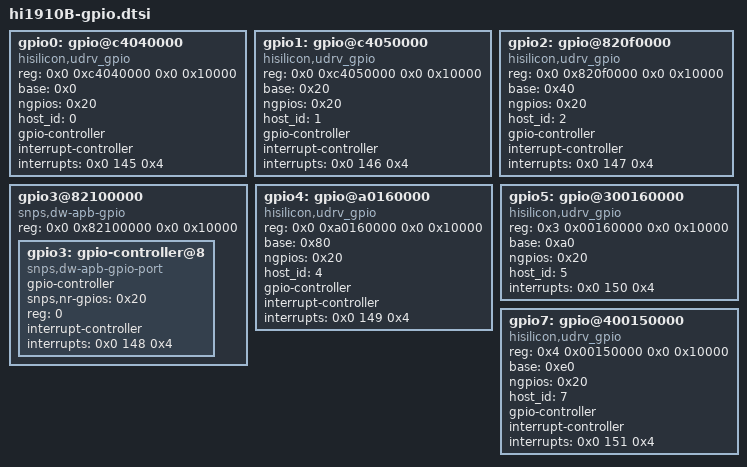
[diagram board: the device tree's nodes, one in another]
	gpio0:gpio@c4040000 {
		compatible = "hisilicon,udrv_gpio";
		reg = <0x0 0xc4040000 0x0 0x10000>;
		base = <0x0>;
		ngpios = <0x20>;
		host_id = <0>;
		gpio-controller;
		#gpio-cells = <2>;
		interrupt-controller;
		#interrupt-cells = <2>;
		interrupts = <0x0 145 0x4>;
	};

	gpio1:gpio@c4050000 {
		compatible = "hisilicon,udrv_gpio";
		reg = <0x0 0xc4050000 0x0 0x10000>;
		base = <0x20>;
		ngpios = <0x20>;
		host_id = <1>;
		gpio-controller;
		#gpio-cells = <2>;
		interrupt-controller;
		#interrupt-cells = <2>;
		interrupts = <0x0 146 0x4>;
	};

	gpio2:gpio@820f0000 {
		compatible = "hisilicon,udrv_gpio";
		reg = <0x0 0x820f0000 0x0 0x10000>;
		base = <0x40>;
		ngpios = <0x20>;
		host_id = <2>;
		gpio-controller;
		#gpio-cells = <2>;
		interrupt-controller;
		#interrupt-cells = <2>;
		interrupts = <0x0 147 0x4>;
	};

	gpio3@82100000 {
		compatible = "snps,dw-apb-gpio";
		reg = <0x0 0x82100000 0x0 0x10000>;
		#address-cells = <1>;
		#size-cells = <0>;

		gpio3:gpio-controller@8 {
			compatible = "snps,dw-apb-gpio-port";
			gpio-controller;
			#gpio-cells = <2>;
			snps,nr-gpios = <0x20>;
			reg = <0>;
			interrupt-controller;
			#interrupt-cells = <2>;
			interrupts = <0x0 148 0x4>;
		};
	};

	gpio4:gpio@a0160000 {
		compatible = "hisilicon,udrv_gpio";
		reg = <0x0 0xa0160000 0x0 0x10000>;
		base = <0x80>;
		ngpios = <0x20>;
		host_id = <4>;
		gpio-controller;
		#gpio-cells = <2>;
		interrupt-controller;
		#interrupt-cells = <2>;
		interrupts = <0x0 149 0x4>;
	};

	gpio5:gpio@300160000 {
		compatible = "hisilicon,udrv_gpio";
		reg = <0x3 0x00160000 0x0 0x10000>;
		base = <0xa0>;
		ngpios = <0x20>;
		host_id = <5>;
		interrupts = <0x0 150 0x4>;
	};

	// gpio6:gpio@a0150000 {
		// compatible = "hisilicon,udrv_gpio";
		// reg = <0x0 0xa0150000 0x0 0x10000>;
		// base = <0xc0>;
		// ngpios = <0x20>;
		// host_id = <6>;
		// gpio-controller;
		// #gpio-cells = <2>;
		// interrupt-controller;
		// #interrupt-cells = <2>;
		// interrupts = <0x0 151 0x4>;
	// };

	gpio7:gpio@400150000 {
		compatible = "hisilicon,udrv_gpio";
		reg = <0x4 0x00150000 0x0 0x10000>;
		base = <0xe0>;
		ngpios = <0x20>;
		host_id = <7>;
		gpio-controller;
		#gpio-cells = <2>;
		interrupt-controller;
		#interrupt-cells = <2>;
		interrupts = <0x0 151 0x4>;
	};
